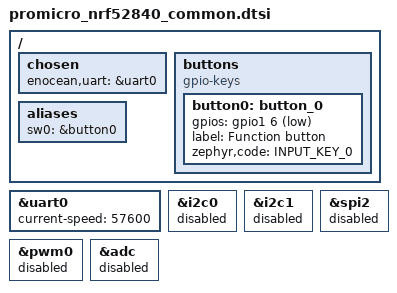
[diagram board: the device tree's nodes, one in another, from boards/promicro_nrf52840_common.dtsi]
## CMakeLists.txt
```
#
# EnOcean-to-Matter-over-Thread gateway.
# Based on the nRF Connect SDK Matter Bridge application
# (Copyright (c) 2023 Nordic Semiconductor ASA, LicenseRef-Nordic-5-Clause).
#

cmake_minimum_required(VERSION 3.20.0)

find_package(Zephyr HINTS $ENV{ZEPHYR_BASE})

project(enocean-matter-gateway)

# Bridge core, Matter identity, network log: firmware/common
include(${CMAKE_CURRENT_SOURCE_DIR}/../common/common.cmake)

target_include_directories(app PRIVATE
  src
  src/enocean
)

target_sources(app PRIVATE
  src/app_task.cpp
  src/main.cpp
  ${GATEWAY_BRIDGED_DEVICE_TYPES}/onoff_light.cpp
  src/enocean/esp3.c
  src/enocean/eep.c
  src/enocean/tcm.c
  src/enocean/enocean_manager.cpp
  src/enocean/enocean_shell.cpp
  src/gateway_shell.cpp
)

# Status page (firmware/common/web): src/web/index.html and its JSON
target_sources_ifdef(CONFIG_GATEWAY_WEB app PRIVATE src/web_status.cpp)

ncs_configure_data_model()
```

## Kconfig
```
#
# EnOcean-to-Matter-over-Thread gateway.
# Based on the nRF Connect SDK Matter Bridge application
# (Copyright (c) 2023 Nordic Semiconductor, LicenseRef-Nordic-5-Clause).
#
mainmenu "EnOcean-to-Matter-over-Thread Gateway"

# The TCM on a UART, interrupt-driven receive into a ring buffer
config SERIAL
	default y

config UART_INTERRUPT_DRIVEN
	default y

config RING_BUFFER
	default y

menu "EnOcean gateway"

config GATEWAY_ENOCEAN_MAX_DEVICES
	int "Maximum number of bridged EnOcean endpoints"
	default 16
	help
	  Each endpoint (an actuator, or one lamp of a two-channel actuator) uses one bridge provider
	  and one dynamic endpoint. See
	  BRIDGE_MAX_BRIDGED_DEVICES_NUMBER and BRIDGE_MAX_DYNAMIC_ENDPOINTS_NUMBER.

config GATEWAY_ENOCEAN_SEEN_MAX
	int "Number of senders kept in the 'heard' table"
	default 16

config GATEWAY_ENOCEAN_QUEUE_SIZE
	int "Telegrams queued between the TCM and Matter threads"
	default 8

config GATEWAY_ENOCEAN_RX_STACK_SIZE
	int "Stack size of the TCM receive thread"
	default 1024

module = GATEWAY_ENOCEAN
module-str = Gateway EnOcean
source "subsys/logging/Kconfig.template.log_config"

endmenu

rsource "../common/Kconfig"
```

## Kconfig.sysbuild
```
#
# EnOcean-to-Matter-over-Thread gateway (nRF52840, single core).
# Based on the nRF Connect SDK Matter Bridge application
# (Copyright (c) 2023 Nordic Semiconductor, LicenseRef-Nordic-5-Clause).
#

# The Pro Micro has no external flash, so there is no room for a second image slot:
# it runs without MCUboot and the app uses the whole internal flash.
choice BOOTLOADER
	default BOOTLOADER_NONE if "$(BOARD)" = "promicro_nrf52840"
	default BOOTLOADER_MCUBOOT
endchoice

# Matter OTA needs MCUboot and the second slot.
config MATTER_OTA
	default n if "$(BOARD)" = "promicro_nrf52840"

if BOOTLOADER_MCUBOOT

config DFU_MULTI_IMAGE_PACKAGE_BUILD
	default y

config DFU_MULTI_IMAGE_PACKAGE_APP
	default y

endif # BOOTLOADER_MCUBOOT

config MATTER_FACTORY_DATA_GENERATE
	default y

source "share/sysbuild/Kconfig"
```

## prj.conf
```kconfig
#
# Copyright (c) 2023 Nordic Semiconductor ASA
#
# SPDX-License-Identifier: LicenseRef-Nordic-5-Clause
#

# This sample uses Kconfig.defaults to set options common for all
# samples. This file should contain only options specific for this sample
# or overrides of default values.

# Enable CHIP
CONFIG_CHIP=y
CONFIG_CHIP_PROJECT_CONFIG="src/chip_project_config.h"
CONFIG_CHIP_DEVICE_PRODUCT_NAME="EnOcean Gateway"

# Configure ZAP file name
CONFIG_NCS_SAMPLE_MATTER_ZAP_FILE_PATH="${APPLICATION_CONFIG_DIR}/src/default_zap/bridge.zap"

# 32771 == 0x8003 (test product ID; the BLE gateway uses 0x8002)
CONFIG_CHIP_DEVICE_PRODUCT_ID=32771
CONFIG_STD_CPP17=y

# Enable Matter pairing automatically on application start.
CONFIG_CHIP_ENABLE_PAIRING_AUTOSTART=y

# Enable Matter extended announcement and increase duration to 1 hour.
CONFIG_CHIP_BLE_EXT_ADVERTISING=y
CONFIG_CHIP_BLE_ADVERTISING_DURATION=60

# Add support for LEDs and buttons on Nordic development kits
CONFIG_DK_LIBRARY=y

# Bluetooth Low Energy configuration
CONFIG_BT_DEVICE_NAME="EnOceanGateway"

# Other settings
CONFIG_THREAD_NAME=y
CONFIG_MPU_STACK_GUARD=y
CONFIG_RESET_ON_FATAL_ERROR=n
CONFIG_CHIP_LIB_SHELL=y
CONFIG_NCS_SAMPLE_MATTER_TEST_SHELL=y

# Reduce assert verbosity to save flash space.
CONFIG_ASSERT_NO_FILE_INFO=y

# Disable NFC onboarding
CONFIG_CHIP_NFC_ONBOARDING_PAYLOAD=n

# Reduce application size
CONFIG_USE_SEGGER_RTT=n

# Enable Factory Data feature
CONFIG_CHIP_FACTORY_DATA=y
CONFIG_CHIP_FACTORY_DATA_BUILD=y

# Increase heap size to accommodate the memory required for additional bridged devices.
CONFIG_CHIP_MALLOC_SYS_HEAP_SIZE=16384

# Enable Shell
CONFIG_SHELL=y
# `enocean add` and `enocean lamps` create endpoints and write the storage on the shell thread.
CONFIG_SHELL_STACK_SIZE=3072

# Peak use was 864 of the default 1152 B (doc/measurements.md)
CONFIG_SYSTEM_WORKQUEUE_STACK_SIZE=1536

# EnOcean: log every actuator command
CONFIG_GATEWAY_ENOCEAN_LOG_LEVEL_INF=y

# Status page over HTTP (firmware/common/web). It needs TCP, which only OpenThread built
# from source has (the prebuilt Nordic library is built without it).
CONFIG_OPENTHREAD_SOURCES=y
CONFIG_GATEWAY_WEB=y
```

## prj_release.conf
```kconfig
#
# Copyright (c) 2023 Nordic Semiconductor ASA
#
# SPDX-License-Identifier: LicenseRef-Nordic-5-Clause
#

# This sample uses Kconfig.defaults to set options common for all
# samples. This file should contain only options specific for this sample
# or overrides of default values.

# Enable CHIP
CONFIG_CHIP=y
CONFIG_CHIP_PROJECT_CONFIG="src/chip_project_config.h"
CONFIG_CHIP_DEVICE_PRODUCT_NAME="EnOcean Gateway"

# Configure ZAP file name
CONFIG_NCS_SAMPLE_MATTER_ZAP_FILE_PATH="${APPLICATION_CONFIG_DIR}/src/default_zap/bridge.zap"

# 32771 == 0x8003 (test product ID; the BLE gateway uses 0x8002)
CONFIG_CHIP_DEVICE_PRODUCT_ID=32771
CONFIG_STD_CPP17=y

# Enable Matter pairing automatically on application start.
CONFIG_CHIP_ENABLE_PAIRING_AUTOSTART=y

# Enable Matter extended announcement and increase duration to 1 hour.
CONFIG_CHIP_BLE_EXT_ADVERTISING=y
CONFIG_CHIP_BLE_ADVERTISING_DURATION=60

# Add support for LEDs and buttons on Nordic development kits
CONFIG_DK_LIBRARY=y

# Bluetooth Low Energy configuration
CONFIG_BT_DEVICE_NAME="EnOceanGateway"

# Enable system reset on fatal error
CONFIG_RESET_ON_FATAL_ERROR=y

# Disable all debug features
CONFIG_USE_SEGGER_RTT=n
CONFIG_OPENTHREAD_SHELL=n
CONFIG_LOG=n
CONFIG_LOG_MODE_MINIMAL=n
CONFIG_ASSERT_VERBOSE=n
CONFIG_ASSERT_NO_FILE_INFO=y
CONFIG_PRINTK=n
CONFIG_PRINTK_SYNC=n
CONFIG_THREAD_NAME=n
CONFIG_BOOT_BANNER=n

# Disable NFC onboarding
CONFIG_CHIP_NFC_ONBOARDING_PAYLOAD=n

# Enable Factory Data feature
CONFIG_CHIP_FACTORY_DATA=y
CONFIG_CHIP_FACTORY_DATA_BUILD=y

# Enable the Read Client for binding purposes
CONFIG_CHIP_ENABLE_READ_CLIENT=y

# Enable Watchdog
CONFIG_NCS_SAMPLE_MATTER_WATCHDOG=y

# Enable LTO to decrease the flash usage.
CONFIG_LTO=y
CONFIG_ISR_TABLES_LOCAL_DECLARATION=y

# Increase heap size to accommodate the memory required for additional bridged devices.
CONFIG_CHIP_MALLOC_SYS_HEAP_SIZE=16384

# Enable Shell
CONFIG_SHELL=y

# Peak use was 864 of the default 1152 B (doc/measurements.md)
CONFIG_SYSTEM_WORKQUEUE_STACK_SIZE=1536

# Status page over HTTP (firmware/common/web). It needs TCP, which only OpenThread built
# from source has (the prebuilt Nordic library is built without it).
CONFIG_OPENTHREAD_SOURCES=y
CONFIG_GATEWAY_WEB=y
```

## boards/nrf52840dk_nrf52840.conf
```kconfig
# One provider and one endpoint per EnOcean endpoint (GATEWAY_ENOCEAN_MAX_DEVICES: actuators and lamps)
CONFIG_BRIDGE_MAX_BRIDGED_DEVICES_NUMBER=16
CONFIG_BRIDGE_MAX_DYNAMIC_ENDPOINTS_NUMBER=16
CONFIG_BRIDGE_MAX_BRIDGED_DEVICES_NUMBER_PER_PROVIDER=1
CONFIG_LTO=y
CONFIG_ISR_TABLES_LOCAL_DECLARATION=y
```

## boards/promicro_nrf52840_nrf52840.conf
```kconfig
# Pro Micro nRF52840, flashed over SWD. Same limits as the DK (boards/nrf52840dk_nrf52840.conf).
CONFIG_BRIDGE_MAX_BRIDGED_DEVICES_NUMBER=16
CONFIG_BRIDGE_MAX_DYNAMIC_ENDPOINTS_NUMBER=16
CONFIG_BRIDGE_MAX_BRIDGED_DEVICES_NUMBER_PER_PROVIDER=1
CONFIG_LTO=y
CONFIG_ISR_TABLES_LOCAL_DECLARATION=y

# Flashed over SWD with the UF2 bootloader erased: link at 0x0, not after the MBR.
CONFIG_BOARD_HAS_NRF5_BOOTLOADER=n
CONFIG_USE_DT_CODE_PARTITION=y

# Many clones have no 32.768 kHz crystal; the RC oscillator works on all of them.
CONFIG_CLOCK_CONTROL_NRF_K32SRC_RC=y
CONFIG_CLOCK_CONTROL_NRF_K32SRC_500PPM=y

# Console and shell run over USB (CDC ACM); the board sets that up itself.

# No MCUboot, so no Matter DFU (see Kconfig.sysbuild).
CONFIG_CHIP_BOOTLOADER_NONE=y
```

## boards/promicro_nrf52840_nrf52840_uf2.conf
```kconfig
# Pro Micro nRF52840 with the UF2 bootloader kept. Same as
# promicro_nrf52840_nrf52840.conf, except the linking: the board's uf2 variant
# links into the DT code partition (0x1000, after the MBR).
CONFIG_BRIDGE_MAX_BRIDGED_DEVICES_NUMBER=16
CONFIG_BRIDGE_MAX_DYNAMIC_ENDPOINTS_NUMBER=16
CONFIG_BRIDGE_MAX_BRIDGED_DEVICES_NUMBER_PER_PROVIDER=1
CONFIG_LTO=y
CONFIG_ISR_TABLES_LOCAL_DECLARATION=y

# Many clones have no 32.768 kHz crystal; the RC oscillator works on all of them.
CONFIG_CLOCK_CONTROL_NRF_K32SRC_RC=y
CONFIG_CLOCK_CONTROL_NRF_K32SRC_500PPM=y

# Console and shell run over USB (CDC ACM); the board sets that up itself.

# No MCUboot, so no Matter DFU (see Kconfig.sysbuild).
CONFIG_CHIP_BOOTLOADER_NONE=y

# Zephyr's own zephyr.uf2 can't find the load address with this partition layout,
# and it would lack the factory data. scripts/make-uf2.py builds gateway.uf2 instead.
CONFIG_BUILD_OUTPUT_UF2=n
```

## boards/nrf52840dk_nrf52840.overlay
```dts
/*
 * Copyright (c) 2021 Nordic Semiconductor ASA
 *
 * SPDX-License-Identifier: LicenseRef-Nordic-5-Clause
 */

#include <samples/matter/nrf52840_partitions.dtsi>

/ {
	chosen {
		nordic,pm-ext-flash = &mx25r64;
		/* TCM 310/515 (EnOcean Pi hat): P1.02 = TX to the module, P1.01 = RX from it
		 * (Arduino header D1/D0, pins from the board's arduino_serial pinctrl). */
		enocean,uart = &uart1;
	};
};

&uart1 {
	status = "okay";
	current-speed = <57600>;
};

&mx25r64 {
	status = "okay";
};

/* Disable unused peripherals to reduce power consumption */
&adc {
	status = "disabled";
};

&i2c0 {
	status = "disabled";
};

&pwm0 {
	status = "disabled";
};

&spi1 {
	status = "disabled";
};

&spi3 {
	status = "disabled";
};

&usbd {
	status = "disabled";
};
```

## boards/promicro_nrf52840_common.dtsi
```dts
/*
 * Pro Micro nRF52840: parts shared by both variants
 * (promicro_nrf52840_nrf52840.overlay for SWD, ..._uf2.overlay for the UF2 bootloader).
 *
 * TCM 310/515 (EnOcean Pi hat) on uart0, the board's default UART pins:
 *   P0.09  TX, to the module's RX
 *   P0.10  RX, from the module's TX
 * plus 3.3 V (VCC) and GND. P0.09/P0.10 are the NFC pins; the board already
 * sets them up as GPIOs (nfct-pins-as-gpios). The console runs over USB.
 */

/ {
	chosen {
		enocean,uart = &uart0;
	};

	/*
	 * Optional function button: a push button between P1.06 and GND.
	 * Hold it about 6 s for a factory reset, as Button 1 on the DK.
	 * Unwired, the pull-up keeps it released.
	 */
	buttons {
		compatible = "gpio-keys";

		button0: button_0 {
			gpios = <&gpio1 6 (GPIO_PULL_UP | GPIO_ACTIVE_LOW)>;
			label = "Function button";
			zephyr,code = <INPUT_KEY_0>;
		};
	};

	aliases {
		sw0 = &button0;
	};
};

&uart0 {
	current-speed = <57600>;
};

/* Unused peripherals. P1.06 above is i2c1's SCL by default. */
&i2c0 {
	status = "disabled";
};

&i2c1 {
	status = "disabled";
};

&spi2 {
	status = "disabled";
};

&pwm0 {
	status = "disabled";
};

&adc {
	status = "disabled";
};
```

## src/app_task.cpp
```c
/*
 * EnOcean-to-Matter-over-Thread gateway.
 * Based on the nRF Connect SDK Matter Bridge application
 * (Copyright (c) 2023 Nordic Semiconductor ASA, LicenseRef-Nordic-5-Clause).
 */

#include "app_task.h"
#include "enocean_manager.h"
#ifdef CONFIG_GATEWAY_IDENTITY_FROM_CHIP_ID
#include "identity/chip_id_identity.h"
#endif
#ifdef CONFIG_GATEWAY_NET_LOG
#include "netlog/net_log.h"
#endif
#ifdef CONFIG_GATEWAY_WEB
#include "web/web_server.h"
#include "web_status.h"
#endif

#include "app/matter_init.h"
#include "app/task_executor.h"
#include "board/board.h"
#include "bridge_manager.h"
#include "bridge_storage_manager.h"
#include "clusters/identify.h"

#include <zephyr/logging/log.h>

LOG_MODULE_DECLARE(app, CONFIG_CHIP_APP_LOG_LEVEL);

using namespace ::chip;
using namespace ::chip::app;
using namespace ::chip::DeviceLayer;

namespace
{

constexpr EndpointId kBridgeEndpointId = 1;

/* Trigger effect is enabled for the bridge device */
Nrf::Matter::IdentifyCluster sIdentifyCluster(kBridgeEndpointId, true);

#ifndef CONFIG_CHIP_FACTORY_RESET_ERASE_SETTINGS
void AppFactoryResetHandler(const ChipDeviceEvent *event, intptr_t /* unused */)
{
	switch (event->Type) {
	case DeviceEventType::kFactoryReset:
		Nrf::BridgeStorageManager::Instance().FactoryReset();
		break;
	default:
		break;
	}
}
#endif

#ifdef CONFIG_GATEWAY_IDENTITY_FROM_CHIP_ID
Gateway::ChipIdFactoryDataProvider sChipIdFactoryDataProvider;
#endif
} /* namespace */

CHIP_ERROR AppTask::RestoreBridgedDevices()
{
	uint8_t count;
	uint8_t indexes[Nrf::BridgeManager::kMaxBridgedDevices] = { 0 };
	size_t indexesCount = 0;

	if (!Nrf::BridgeStorageManager::Instance().LoadBridgedDevicesCount(count)) {
		LOG_INF("No bridged devices to load from the storage.");
		return CHIP_NO_ERROR;
	}

	if (!Nrf::BridgeStorageManager::Instance().LoadBridgedDevicesIndexes(
		    indexes, Nrf::BridgeManager::kMaxBridgedDevices, indexesCount)) {
		return CHIP_NO_ERROR;
	}

	for (size_t i = 0; i < indexesCount; i++) {
		Nrf::BridgeStorageManager::BridgedDevice device;
		Gateway::EnOceanUserData userData{};

		device.mUserData = reinterpret_cast<uint8_t *>(&userData);
		device.mUserDataSize = sizeof(userData);

		if (!Nrf::BridgeStorageManager::Instance().LoadBridgedDevice(device, indexes[i])) {
			return CHIP_ERROR_NOT_FOUND;
		}
		if (device.mUserDataSize != sizeof(userData)) {
			LOG_WRN("Stored device %u is not an EnOcean actuator, skipped", indexes[i]);
			continue;
		}

		CHIP_ERROR err = Gateway::EnOceanManager::Instance().Restore(userData, device.mDeviceType,
									     device.mUniqueID, device.mNodeLabel,
									     indexes[i], device.mEndpointId);
		if (err != CHIP_NO_ERROR) {
			LOG_ERR("Cannot restore device %u: %" CHIP_ERROR_FORMAT, indexes[i], err.Format());
		}
	}
	return CHIP_NO_ERROR;
}

CHIP_ERROR AppTask::Init()
{
	/* Initialize Matter stack */
	ReturnErrorOnFailure(Nrf::Matter::PrepareServer(Nrf::Matter::InitData{
#ifdef CONFIG_GATEWAY_IDENTITY_FROM_CHIP_ID
		.mFactoryDataProvider = &sChipIdFactoryDataProvider,
#endif
		.mPostServerInitClbk = [] {
		CHIP_ERROR err = Nrf::BridgeManager::Instance().Init(RestoreBridgedDevices);
		if (err != CHIP_NO_ERROR) {
			LOG_ERR("BridgeManager initialization failed");
			return err;
		}

		/* A missing or unwired TCM is not fatal: Matter keeps running, sending fails. */
		if (Gateway::EnOceanManager::Instance().Start() != CHIP_NO_ERROR) {
			LOG_ERR("EnOcean TCM initialization failed");
		}
#ifdef CONFIG_GATEWAY_NET_LOG
		Gateway::NetLog::Init();
#endif
#ifdef CONFIG_GATEWAY_WEB
		Gateway::Web::Init(Gateway::WriteWebStatus);
#endif
		return CHIP_NO_ERROR;
	} }));

	if (!Nrf::GetBoard().Init()) {
		LOG_ERR("User interface initialization failed.");
		return CHIP_ERROR_INCORRECT_STATE;
	}

	/* Register Matter event handler that controls the connectivity status LED based on the captured Matter
	 * network state. */
	ReturnErrorOnFailure(Nrf::Matter::RegisterEventHandler(Nrf::Board::DefaultMatterEventHandler, 0));

#ifndef CONFIG_CHIP_FACTORY_RESET_ERASE_SETTINGS
	/* The whole settings partition is not erased on factory reset; clean up the bridge storage. */
	ReturnErrorOnFailure(Nrf::Matter::RegisterEventHandler(AppFactoryResetHandler, 0));
#endif

	ReturnErrorOnFailure(sIdentifyCluster.Init());

	return Nrf::Matter::StartServer();
}

CHIP_ERROR AppTask::StartApp()
{
	ReturnErrorOnFailure(Init());

	while (true) {
		Nrf::DispatchNextTask();
	}

	return CHIP_NO_ERROR;
}
```

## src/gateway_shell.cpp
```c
/*
 * `gateway ...` shell commands of the EnOcean gateway (shared with the BLE gateway,
 * firmware/common/identity/identity_shell.h):
 *   gateway identity     chip ID, serial number and Matter setup code
 *   gateway bootloader   restart into the UF2 bootloader (Pro Micro UF2 builds)
 */

#include "identity/identity_shell.h"

#include <zephyr/shell/shell.h>

SHELL_STATIC_SUBCMD_SET_CREATE(
	sub_gateway,
	SHELL_CMD_ARG(identity, NULL, "Show chip ID, serial number and the Matter setup code.",
		      Gateway::IdentityShell::CmdIdentity, 1, 0),
	SHELL_COND_CMD_ARG(IS_ENABLED(CONFIG_GATEWAY_UF2_BOOTLOADER_CMD), bootloader, NULL,
			   "Restart into the UF2 bootloader, which then shows up as a USB drive.",
			   COND_CODE_1(CONFIG_GATEWAY_UF2_BOOTLOADER_CMD, (Gateway::IdentityShell::CmdBootloader),
				       (NULL)),
			   1, 0),
	SHELL_SUBCMD_SET_END);

SHELL_CMD_REGISTER(gateway, &sub_gateway, "Gateway identity", NULL);
```

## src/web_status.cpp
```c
/*
 * Status JSON of the EnOcean gateway for the web page (src/web/index.html). See web_status.h.
 */

#include "web_status.h"

#include "bridge_manager.h"
#include "enocean_manager.h"
#include "matter_bridged_device.h"
#include "tcm.h"
#include "web/status_json.h"

#include <platform/CHIPDeviceLayer.h>

#include <zephyr/kernel.h>

#include <stdio.h>
#include <string.h>

using namespace chip;
using Gateway::Web::Json;
using Gateway::EnOceanManager;
using Gateway::EnOceanUserData;
using Nrf::MatterBridgedDevice;

namespace
{

void WriteTcm(Json &j)
{
	tcm_info info;
	char text[16];

	tcm_get_info(&info);
	j.Open("tcm", '{');
	j.Bool("ok", info.base_id != 0);
	snprintf(text, sizeof(text), "%u.%u.%u.%u", info.app_version[0], info.app_version[1], info.app_version[2],
		 info.app_version[3]);
	j.Str("app", text);
	snprintf(text, sizeof(text), "%08X", unsigned(info.base_id));
	j.Str("baseId", text);
	j.Int("changesLeft", info.base_id_changes_left);
	j.Int("received", info.stats.packets);
	j.Int("crcErrors", info.stats.header_crc_errors + info.stats.data_crc_errors);
	j.Int("overruns", info.rx_overruns);
	j.Int("sent", info.sent);
	j.Int("sendErrors", info.send_errors);
	j.Close('}');
}

void WriteDevices(Json &j)
{
	static EnOceanManager::DeviceInfo devices[EnOceanManager::kMaxDevices];
	const size_t n = EnOceanManager::Instance().GetDevices(devices, ARRAY_SIZE(devices));
	const int64_t now = k_uptime_get();
	char text[12];

	j.Open("devices", '[');
	for (size_t i = 0; i < n; i++) {
		const auto &d = devices[i];
		uint8_t index;
		const MatterBridgedDevice *device = Nrf::BridgeManager::Instance().GetDevice(d.mEndpoint, index);

		j.Open(nullptr, '{');
		snprintf(text, sizeof(text), "%08X", unsigned(d.mData.mId));
		j.Str("id", text);
		j.Int("endpoint", d.mEndpoint);
		j.Str("name", device ? device->GetNodeLabel() : "");
		j.Str("kind", d.mData.mKind == EnOceanUserData::kEltako ? "eltako" : "d2");
		j.Str("type", d.mDeviceType == MatterBridgedDevice::DeviceType::OnOffPlugInUnit ? "plug" : "light");
		j.Int("lamp", d.mData.mContact);
		j.Int("offset", d.mData.mOffset);
		if (d.mData.mContact) {
			j.Int("stepOffset", d.mData.mStepOffset);
		}
		if (d.mStateKnown) {
			j.Bool("on", d.mOn);
		} else {
			j.Null("on");
		}
		j.Int("contacts", d.mContacts);
		j.Int("contactsSeen", d.mContactsSeen);
		j.Bool("stepping", d.mStepping);
		if (d.mHasPower) {
			j.Int("powerW", d.mPowerW);
		} else {
			j.Null("powerW");
		}
		if (d.mLastSeenMs) {
			j.Int("dbm", d.mDbm);
			j.Int("lastSeenS", (now - d.mLastSeenMs) / 1000);
		} else {
			j.Null("lastSeenS");
		}
		j.Close('}');
	}
	j.Close(']');
}

void WriteSeen(Json &j)
{
	static EnOceanManager::SeenInfo seen[EnOceanManager::kMaxSeen];
	const size_t n = EnOceanManager::Instance().GetSeen(seen, ARRAY_SIZE(seen));
	const int64_t now = k_uptime_get();
	char text[12];

	j.Open("seen", '[');
	for (size_t i = 0; i < n; i++) {
		const auto &s = seen[i];

		j.Open(nullptr, '{');
		snprintf(text, sizeof(text), "%08X", unsigned(s.mId));
		j.Str("id", text);
		snprintf(text, sizeof(text), "%02X", s.mRorg);
		j.Str("rorg", text);
		for (uint8_t b = 0; b < s.mLen && b < 4; b++) {
			snprintf(&text[2 * b], sizeof(text) - 2 * b, "%02X", s.mPayload[b]);
		}
		j.Str("data", s.mLen ? text : "");
		j.Int("dbm", s.mDbm);
		j.Int("hops", s.mRepeaters);
		j.Int("count", s.mCount);
		j.Int("repeated", s.mRepeatedCount);
		j.Int("agoS", (now - s.mLastSeenMs) / 1000);
		j.Close('}');
	}
	j.Close(']');
}

} /* namespace */

namespace Gateway
{

size_t WriteWebStatus(char *buf, size_t size)
{
	Json j(buf, size);

	j.Open(nullptr, '{');
	Gateway::Web::WriteCommonStatus(j);
	WriteTcm(j);
	WriteDevices(j);
	WriteSeen(j);
	j.Close('}');
	return j.Done();
}

} /* namespace Gateway */
```

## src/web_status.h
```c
/*
 * Status JSON of the EnOcean gateway for the web page (src/web/index.html):
 * system, Thread, Matter, TCM, bridged actuators and the senders heard.
 */

#pragma once

#include <stddef.h>

namespace Gateway
{

/* A Gateway::Web::StatusWriter: Matter thread, returns 0 if the JSON does not fit. */
size_t WriteWebStatus(char *buf, size_t size);

} /* namespace Gateway */
```
